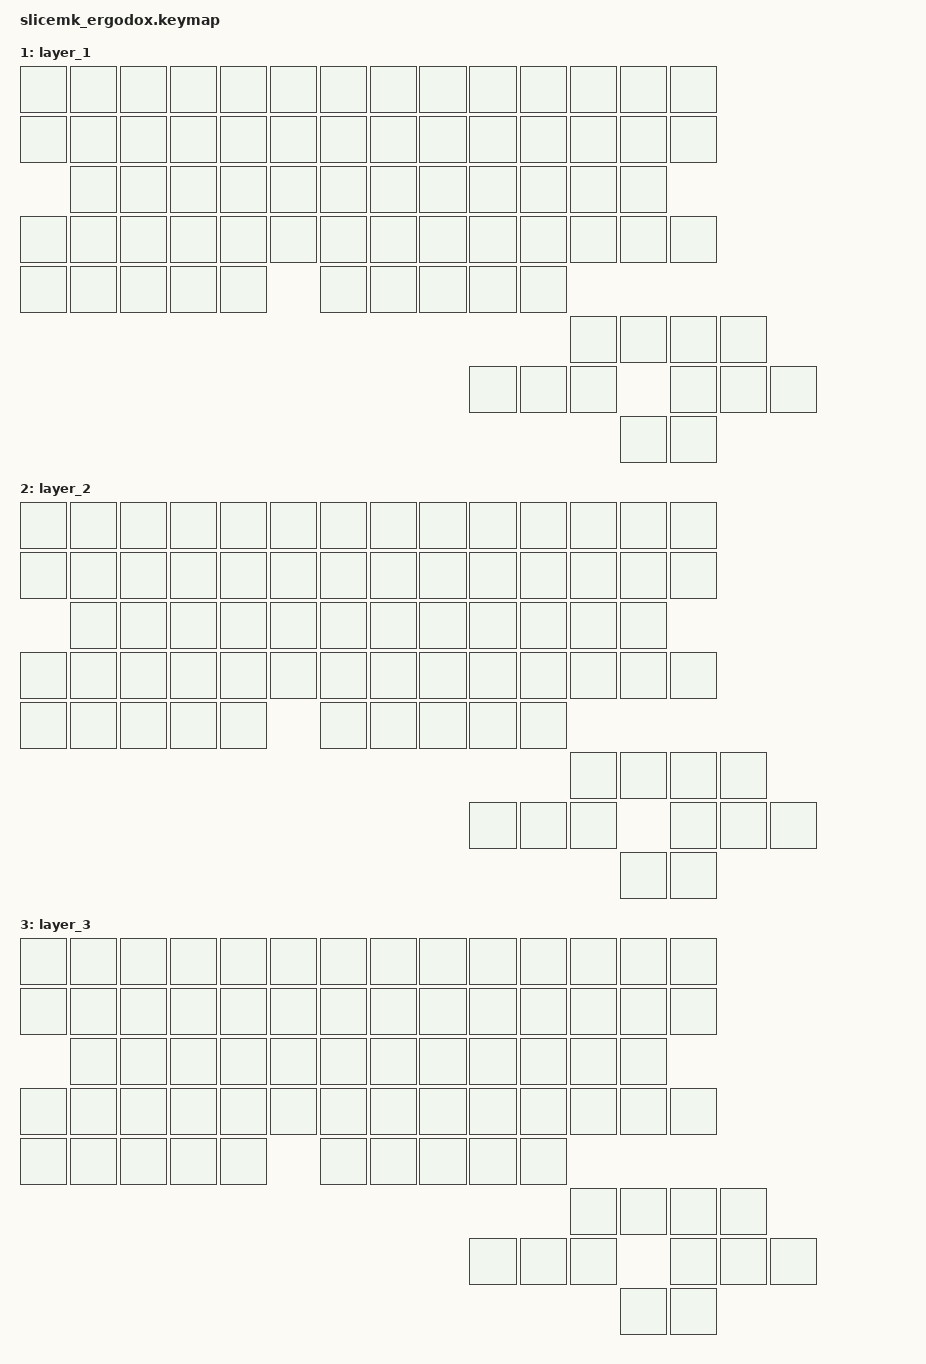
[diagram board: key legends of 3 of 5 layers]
#include <behaviors.dtsi>
#include <dt-bindings/zmk/bt.h>
#include <dt-bindings/zmk/keys.h>
#include <dt-bindings/zmk/mouse.h>
#include <dt-bindings/zmk/outputs.h>

#define LAYER_MAIN 0
#define LAYER_FN 1
#define LAYER_SYMB 2
#define LAYER_NMPAD 3
#define LAYER_MOUSE 4

/ {
	keymap {
		compatible = "zmk,keymap";
		layer_0 {
			bindings = <
				&none &none &none &none &none &none &none &none &none &none &none &none &none &none
				&none &none &none &none &none &none &none &none &none &none &none &none &none &none
			        &none &none &none &none &none &none &none &none &none &none &none &none 
				&none &none &none &none &none &none &none &none &none &none &none &none &none &none
                                &none &none &none &none &none       &none &none &none &none &none
				                                                                 &none &none &none &none
				                                                   &none         &none &none &none &none
				                                                                       &none &none
			>;
		};

		layer_1 {
			bindings = <
				&none &none &none &none &none &none &none &none &none &none &none &none &none &none
				&none &none &none &none &none &none &none &none &none &none &none &none &none &none
			        &none &none &none &none &none &none &none &none &none &none &none &none 
				&none &none &none &none &none &none &none &none &none &none &none &none &none &none
				&none &none &none &none &none       &none &none &none &none &none
				                                                                 &none &none &none &none
				                                                    &none        &none &none &none &none &none
				                                                                       &none &none
			>;
		};

		layer_2 {
			bindings = <
				&none &none &none &none &none &none &none &none &none &none &none &none &none &none
				&none &none &none &none &none &none &none &none &none &none &none &none &none &none
			        &none &none &none &none &none &none &none &none &none &none &none &none 
				&none &none &none &none &none &none &none &none &none &none &none &none &none &none
				&none &none &none &none &none       &none &none &none &none &none
				                                                                 &none &none &none &none
				                                                    &none        &none &none &none &none &none
				                                                                       &none &none
			>;
		};

		layer_3 {
			bindings = <
				&none &none &none &none &none &none &none &none &none &none &none &none &none &none
				&none &none &none &none &none &none &none &none &none &none &none &none &none &none
			        &none &none &none &none &none &none &none &none &none &none &none &none 
				&none &none &none &none &none &none &none &none &none &none &none &none &none &none
				&none &none &none &none &none       &none &none &none &none &none
				                                                                 &none &none &none &none
				                                                    &none        &none &none &none &none &none
				                                                                       &none &none
			>;
		};

		layer_4 {
			bindings = <
                                &bootloader
				&none &none &none &none &none &none &none &none &none &none &none &none &none &none
				&none &none &none &none &none &none &none &none &none &none &none &none &none &none
			        &none &none &none &none &none &none &none &none &none &none &none &none 
				&none &none &none &none &none &none &none &none &none &none &none &none &none &none
				&none &none &none &none &none       &none &none &none &none &none
				                                                                 &none &none &none &none
				                                                    &none        &none &none &none &none &none
				                                                                       &none &none
			>;
		};
	};
};
